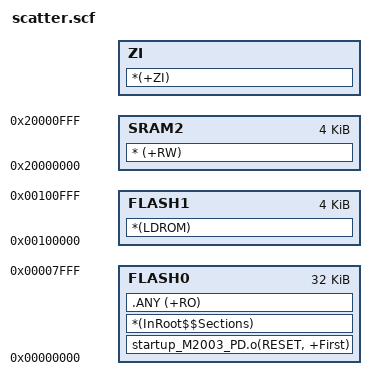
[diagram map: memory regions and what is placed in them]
APROMFLASH 0x00000000
{
    FLASH0 +0 0x8000
    {
	    startup_M2003_PD.o(RESET, +First)
        *(InRoot$$Sections)
	    .ANY (+RO)
    }

    SRAM2 0x20000000 0x1000
    {
        * (+RW)
    }

    ZI +0
    {
        *(+ZI)
    }
}

LDROMFLASH 0x00100000
{
	FLASH1 +0 0x1000
	{
		*(LDROM)
	}
}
